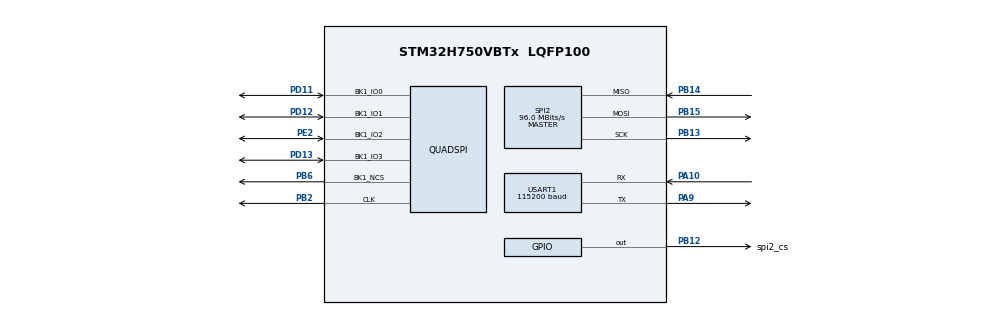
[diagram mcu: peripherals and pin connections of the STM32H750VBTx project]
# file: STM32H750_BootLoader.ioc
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Mcu.Family=STM32H7
Mcu.Name=STM32H750VBTx
Mcu.Package=LQFP100
NVIC.PriorityGroup=NVIC_PRIORITYGROUP_4
NVIC.USART1_IRQn=true\:2\:0\:true\:false\:true\:true\:true\:true
PA10.Mode=Asynchronous
PA10.Signal=USART1_RX
PA13\ (JTMS/SWDIO).Mode=Serial_Wire
PA13\ (JTMS/SWDIO).Signal=DEBUG_JTMS-SWDIO
PA14\ (JTCK/SWCLK).Mode=Serial_Wire
PA14\ (JTCK/SWCLK).Signal=DEBUG_JTCK-SWCLK
PA9.Mode=Asynchronous
PA9.Signal=USART1_TX
PB12.GPIO_Label=spi2_cs
PB12.GPIO_Speed=GPIO_SPEED_FREQ_VERY_HIGH
PB12.Signal=GPIO_Output
PB13.GPIO_Speed=GPIO_SPEED_FREQ_VERY_HIGH
PB13.Mode=Full_Duplex_Master
PB13.Signal=SPI2_SCK
PB14.GPIO_Speed=GPIO_SPEED_FREQ_VERY_HIGH
PB14.Mode=Full_Duplex_Master
PB14.Signal=SPI2_MISO
PB15.GPIO_Speed=GPIO_SPEED_FREQ_VERY_HIGH
PB15.Mode=Full_Duplex_Master
PB15.Signal=SPI2_MOSI
PB2.GPIO_Speed=GPIO_SPEED_FREQ_VERY_HIGH
PB2.Mode=Single Bank 1
PB2.Signal=QUADSPI_CLK
PB6.GPIO_Speed=GPIO_SPEED_FREQ_VERY_HIGH
PB6.Mode=Single Bank 1
PB6.Signal=QUADSPI_BK1_NCS
PD11.GPIO_Speed=GPIO_SPEED_FREQ_VERY_HIGH
PD11.Mode=Single Bank 1
PD11.Signal=QUADSPI_BK1_IO0
PD12.GPIO_Speed=GPIO_SPEED_FREQ_VERY_HIGH
PD12.Mode=Single Bank 1
PD12.Signal=QUADSPI_BK1_IO1
PD13.GPIO_Speed=GPIO_SPEED_FREQ_VERY_HIGH
PD13.Mode=Single Bank 1
PD13.Signal=QUADSPI_BK1_IO3
PE2.GPIO_Speed=GPIO_SPEED_FREQ_VERY_HIGH
PE2.Mode=Single Bank 1
PE2.Signal=QUADSPI_BK1_IO2
ProjectManager.HeapSize=0x200
ProjectManager.StackSize=0x400
ProjectManager.TargetToolchain=MDK-ARM V5.27
QUADSPI.ChipSelectHighTime=QSPI_CS_HIGH_TIME_4_CYCLE
QUADSPI.ClockPrescaler=1
QUADSPI.FifoThreshold=4
QUADSPI.FlashSize=22
QUADSPI.SampleShifting=QSPI_SAMPLE_SHIFTING_HALFCYCLE
RCC.ADCFreq_Value=129000000
RCC.APB1Freq_Value=120000000
RCC.APB2Freq_Value=120000000
RCC.APB3Freq_Value=120000000
RCC.APB4Freq_Value=120000000
RCC.CortexFreq_Value=480000000
RCC.D1PPRE=RCC_APB3_DIV2
RCC.D2PPRE1=RCC_APB1_DIV2
RCC.D2PPRE2=RCC_APB2_DIV2
RCC.D3PPRE=RCC_APB4_DIV2
RCC.DIVM1=4
RCC.DIVN1=60
RCC.DIVQ1=5
RCC.HCLKFreq_Value=240000000
RCC.HPRE=RCC_HCLK_DIV2
RCC.PLLFRACN=0
RCC.SYSCLKFreq_VALUE=480000000
RCC.SYSCLKSource=RCC_SYSCLKSOURCE_PLLCLK
RCC.USBFreq_Value=192000000
SPI2.CalculateBaudRate=96.0 MBits/s
SPI2.DataSize=SPI_DATASIZE_8BIT
SPI2.Direction=SPI_DIRECTION_2LINES
SPI2.Mode=SPI_MODE_MASTER
SPI2.VirtualType=VM_MASTER
USART1.BaudRate=115200
USART1.VirtualMode-Asynchronous=VM_ASYNC
board=custom

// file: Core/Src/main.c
/* USER CODE BEGIN Header */
/**
  ******************************************************************************
  * @file           : main.c
  * @brief          : Main program body
  ******************************************************************************
  * @attention
  *
  * Copyright (c) 2022 STMicroelectronics.
  * All rights reserved.
  *
  * This software is licensed under terms that can be found in the LICENSE file
  * in the root directory of this software component.
  * If no LICENSE file comes with this software, it is provided AS-IS.
  *
  ******************************************************************************
  */
/* USER CODE END Header */
#include "main.h"
#include "quadspi.h"
#include "spi.h"
#include "usart.h"
#include "gpio.h"

/* USER CODE BEGIN Includes */
#include "public.h"
#include "qspi_norflash.h"
/* USER CODE END Includes */

void SystemClock_Config(void);

int main(void)
{

  /* MCU Configuration--------------------------------------------------------*/

  /* Reset of all peripherals, Initializes the Flash interface and the Systick. */
  HAL_Init();

  /* Configure the system clock */
  SystemClock_Config();

  /* Initialize all configured peripherals */
  MX_GPIO_Init();
  MX_USART1_UART_Init();
  MX_QUADSPI_Init();
  MX_SPI2_Init();
  /* USER CODE BEGIN 2 */
	/* 初始化外部flash并进入内存映射模式 */
//	BSP_QSPI_Init();
//	QSPI_EnableMemoryMappedMode();
	run();
  /* USER CODE END 2 */

  /* Infinite loop */
  while (1)
  {

  }
}

void SystemClock_Config(void)
{
  RCC_OscInitTypeDef RCC_OscInitStruct = {0};
  RCC_ClkInitTypeDef RCC_ClkInitStruct = {0};

  /** Supply configuration update enable
  */
  HAL_PWREx_ConfigSupply(PWR_LDO_SUPPLY);

  /** Configure the main internal regulator output voltage
  */
  __HAL_PWR_VOLTAGESCALING_CONFIG(PWR_REGULATOR_VOLTAGE_SCALE1);

  while(!__HAL_PWR_GET_FLAG(PWR_FLAG_VOSRDY)) {}

  __HAL_RCC_SYSCFG_CLK_ENABLE();
  __HAL_PWR_VOLTAGESCALING_CONFIG(PWR_REGULATOR_VOLTAGE_SCALE0);

  while(!__HAL_PWR_GET_FLAG(PWR_FLAG_VOSRDY)) {}

  /** Initializes the RCC Oscillators according to the specified parameters
  * in the RCC_OscInitTypeDef structure.
  */
  RCC_OscInitStruct.OscillatorType = RCC_OSCILLATORTYPE_HSI;
  RCC_OscInitStruct.HSIState = RCC_HSI_DIV1;
  RCC_OscInitStruct.HSICalibrationValue = RCC_HSICALIBRATION_DEFAULT;
  RCC_OscInitStruct.PLL.PLLState = RCC_PLL_ON;
  RCC_OscInitStruct.PLL.PLLSource = RCC_PLLSOURCE_HSI;
  RCC_OscInitStruct.PLL.PLLM = 4;
  RCC_OscInitStruct.PLL.PLLN = 60;
  RCC_OscInitStruct.PLL.PLLP = 2;
  RCC_OscInitStruct.PLL.PLLQ = 5;
  RCC_OscInitStruct.PLL.PLLR = 2;
  RCC_OscInitStruct.PLL.PLLRGE = RCC_PLL1VCIRANGE_3;
  RCC_OscInitStruct.PLL.PLLVCOSEL = RCC_PLL1VCOWIDE;
  RCC_OscInitStruct.PLL.PLLFRACN = 0;
  if (HAL_RCC_OscConfig(&RCC_OscInitStruct) != HAL_OK)
  {
    Error_Handler();
  }

  /** Initializes the CPU, AHB and APB buses clocks
  */
  RCC_ClkInitStruct.ClockType = RCC_CLOCKTYPE_HCLK|RCC_CLOCKTYPE_SYSCLK
                              |RCC_CLOCKTYPE_PCLK1|RCC_CLOCKTYPE_PCLK2
                              |RCC_CLOCKTYPE_D3PCLK1|RCC_CLOCKTYPE_D1PCLK1;
  RCC_ClkInitStruct.SYSCLKSource = RCC_SYSCLKSOURCE_PLLCLK;
  RCC_ClkInitStruct.SYSCLKDivider = RCC_SYSCLK_DIV1;
  RCC_ClkInitStruct.AHBCLKDivider = RCC_HCLK_DIV2;
  RCC_ClkInitStruct.APB3CLKDivider = RCC_APB3_DIV2;
  RCC_ClkInitStruct.APB1CLKDivider = RCC_APB1_DIV2;
  RCC_ClkInitStruct.APB2CLKDivider = RCC_APB2_DIV2;
  RCC_ClkInitStruct.APB4CLKDivider = RCC_APB4_DIV2;

  if (HAL_RCC_ClockConfig(&RCC_ClkInitStruct, FLASH_LATENCY_4) != HAL_OK)
  {
    Error_Handler();
  }
}

void Error_Handler(void)
{
  __disable_irq();
  while (1)
  {
  }
}
